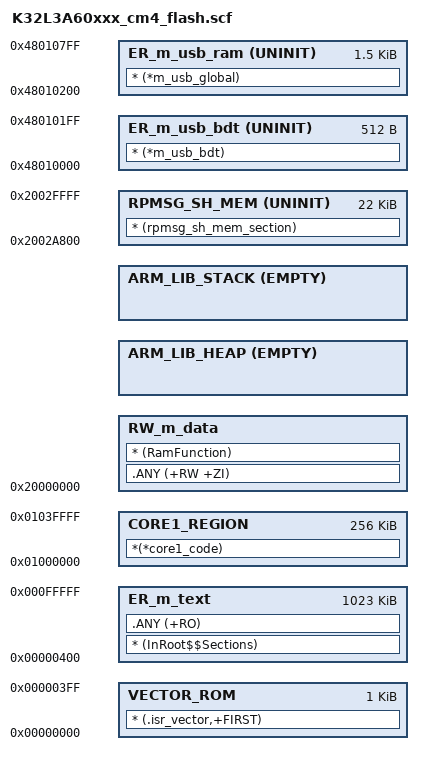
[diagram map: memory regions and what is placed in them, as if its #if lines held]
#!armclang --target=arm-arm-none-eabi -mcpu=cortex-m4 -E -x c
/*
** ###################################################################
**     Processor:           K32L3A60VPJ1A_cm4
**     Compiler:            Keil ARM C/C++ Compiler
**     Reference manual:    K32L3ARM, Rev. 0 , 05/2019
**     Version:             rev. 1.0, 2019-04-22
**     Build:               b191008
**
**     Abstract:
**         Linker file for the Keil ARM C/C++ Compiler
**
**     Copyright 2016 Freescale Semiconductor, Inc.
**     Copyright 2016-2019 NXP
**     All rights reserved.
**
**     SPDX-License-Identifier: BSD-3-Clause
**
**     http:                 www.nxp.com
**     mail:                 support@nxp.com
**
** ###################################################################
*/

#define m_interrupts_start             0x00000000
#define m_interrupts_size              0x00000400

#define m_text_start                   0x00000400
#define m_text_size                    0x000FFC00

#define m_core1_image_start            0x01000000
#define m_core1_image_size             0x00040000

#if (defined(__use_shmem__))
  #define m_data_start                 0x20000000
  #define m_data_size                  0x0002A800
  #define m_rpmsg_sh_mem_start         0x2002A800
  #define m_rpmsg_sh_mem_size          0x00005800
#else
  #define m_data_start                 0x20000000
  #define m_data_size                  0x00030000
#endif

#define m_usb_sram_start               0x48010000
#define m_usb_sram_size                0x00000800

/* USB BDT size */
#define usb_bdt_size                   0x200

/* Sizes */
#if (defined(__stack_size__))
  #define Stack_Size                   __stack_size__
#else
  #define Stack_Size                   0x0400
#endif

#if (defined(__heap_size__))
  #define Heap_Size                    __heap_size__
#else
  #define Heap_Size                    0x0400
#endif

LR_m_text m_interrupts_start m_text_start+m_text_size-m_interrupts_start { ; load region size_region
  VECTOR_ROM m_interrupts_start m_interrupts_size { ; load address = execution address
    * (.isr_vector,+FIRST)
  }
  ER_m_text m_text_start m_text_size { ; load address = execution address
    * (InRoot$$Sections)
    .ANY (+RO)
  }

#if (defined(__use_shmem__))
  RPMSG_SH_MEM m_rpmsg_sh_mem_start UNINIT m_rpmsg_sh_mem_size { ; Shared memory used by RPMSG
    * (rpmsg_sh_mem_section)
  }
#endif

  RW_m_data m_data_start m_data_size-Stack_Size-Heap_Size { ; RW data
    .ANY (+RW +ZI)
    * (RamFunction)
  }
  ARM_LIB_HEAP +0 EMPTY Heap_Size {    ; Heap region growing up
  }
  ARM_LIB_STACK m_data_start+m_data_size EMPTY -Stack_Size { ; Stack region growing down
  }
}

LR_m_usb_bdt m_usb_sram_start usb_bdt_size {
  ER_m_usb_bdt m_usb_sram_start UNINIT usb_bdt_size {
    * (*m_usb_bdt)
  }
}

LR_m_usb_ram (m_usb_sram_start + usb_bdt_size) (m_usb_sram_size - usb_bdt_size) {
  ER_m_usb_ram (m_usb_sram_start + usb_bdt_size) UNINIT (m_usb_sram_size - usb_bdt_size) {
    * (*m_usb_global)
  }
}

LR_CORE1_IMAGE m_core1_image_start {
  CORE1_REGION m_core1_image_start m_core1_image_size {
    *(*core1_code)
  }
}
